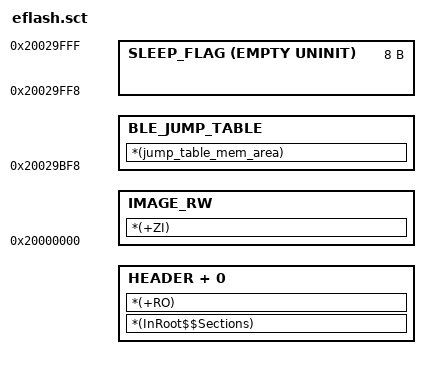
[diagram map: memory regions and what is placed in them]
; *************************************************************
; *** Scatter-Loading Description File generated by uVision ***
; *************************************************************

SOC 0x10000000 0x3C000  ; 240KB
{
    STARTUP + 0 
    {
        *(VECTOR_TABLE, +First)
    }

    HEADER + 0 FIXED                ;should always start from offset 0xC0
    {
        *(IMAGE_HEADER, +First)
    }

    IMAGE_RO + 0
    {
        *(InRoot$$Sections)        
        *(+RO)
    }

    IMAGE_RW 0x20000000
    {
        *(+RW)
        *(RO_IN_SYS_RAM)
    }

    IMAGE_ZI + 0
    {
        *(+ZI)
    }

    BLE_JUMP_TABLE 0x20029BF8 
    {
        *(jump_table_mem_area)
    }

    SLEEP_FLAG 0x20029FF8 EMPTY UNINIT 0x8      ; save deep sleep flag and key to the bottom of RAM address
    {
        ;     +-----------------+
        ;0x00 |   0xBEEFBEEF    |
        ;     +-----------------+
        ;0x04 | &Wakeup_Handler |
        ;     +-----------------+
    }
}


